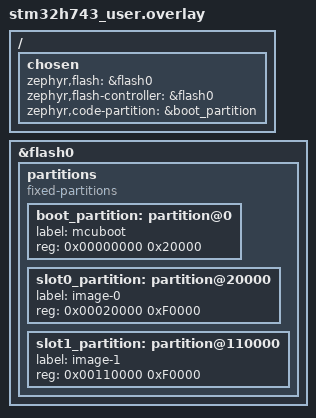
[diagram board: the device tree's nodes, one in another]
/ {
	chosen {
		zephyr,flash = &flash0;
		zephyr,flash-controller = &flash0;
		zephyr,code-partition = &boot_partition;
	};
};

&flash0 {
	ranges;
	partitions {
		compatible = "fixed-partitions";
		#address-cells = <1>;
		#size-cells = <1>;

		boot_partition: partition@0 {
			label = "mcuboot";
			reg = <0x00000000 0x20000>;
		};

		slot0_partition: partition@20000 {
			label = "image-0";
			reg = <0x00020000 0xF0000>;
		};

		slot1_partition: partition@110000 {
			label = "image-1";
			reg = <0x00110000 0xF0000>;
		};
	};
};
